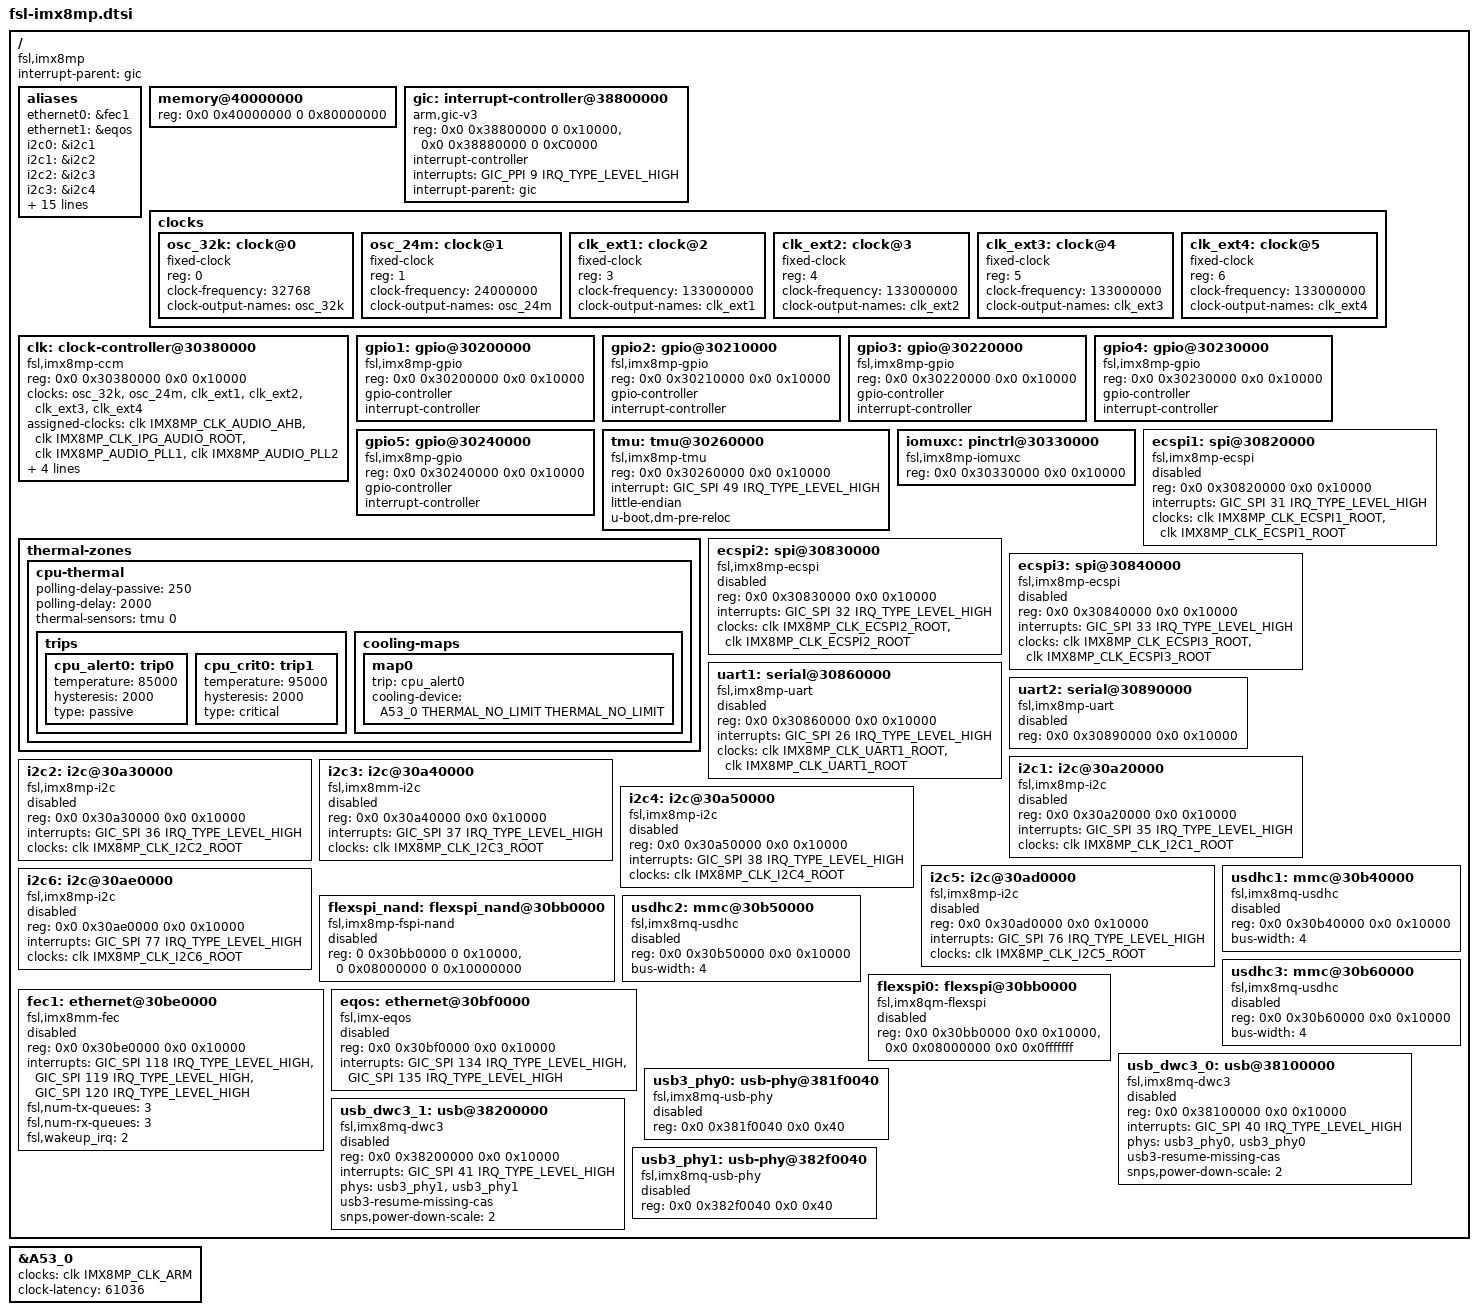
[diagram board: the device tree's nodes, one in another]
/*
 * Copyright 2019 NXP
 *
 * This program is free software; you can redistribute it and/or
 * modify it under the terms of the GNU General Public License
 * as published by the Free Software Foundation; either version 2
 * of the License, or (at your option) any later version.
 *
 * This program is distributed in the hope that it will be useful,
 * but WITHOUT ANY WARRANTY; without even the implied warranty of
 * MERCHANTABILITY or FITNESS FOR A PARTICULAR PURPOSE.  See the
 * GNU General Public License for more details.
 */

#include "fsl-imx8-ca53.dtsi"
#include <dt-bindings/clock/imx8mp-clock.h>
#include <dt-bindings/gpio/gpio.h>
#include <dt-bindings/input/input.h>
#include <dt-bindings/interrupt-controller/arm-gic.h>
#include <dt-bindings/pinctrl/pins-imx8mp.h>
#include <dt-bindings/thermal/thermal.h>

/ {
	compatible = "fsl,imx8mp";
	interrupt-parent = <&gic>;
	#address-cells = <2>;
	#size-cells = <2>;

	aliases {
		ethernet0 = &fec1;
		ethernet1 = &eqos;
		i2c0 = &i2c1;
		i2c1 = &i2c2;
		i2c2 = &i2c3;
		i2c3 = &i2c4;
		i2c4 = &i2c5;
		i2c5 = &i2c6;
		serial0 = &uart1;
		serial1 = &uart2;
		gpio0 = &gpio1;
		gpio1 = &gpio2;
		gpio2 = &gpio3;
		gpio3 = &gpio4;
		gpio4 = &gpio5;
		mmc0 = &usdhc1;
		mmc1 = &usdhc2;
		mmc2 = &usdhc3;
		usb0 = &usb_dwc3_0;
		usb1 = &usb_dwc3_1;
		spi0 = &flexspi0;
	};

	memory@40000000 {
		device_type = "memory";
		reg = <0x0 0x40000000 0 0x80000000>;
	};

	gic: interrupt-controller@38800000 {
		compatible = "arm,gic-v3";
		reg = <0x0 0x38800000 0 0x10000>, /* GIC Dist */
		      <0x0 0x38880000 0 0xC0000>; /* GICR (RD_base + SGI_base) */
		#interrupt-cells = <3>;
		interrupt-controller;
		interrupts = <GIC_PPI 9 IRQ_TYPE_LEVEL_HIGH>;
		interrupt-parent = <&gic>;
	};

	clocks {
		#address-cells = <1>;
		#size-cells = <0>;

		osc_32k: clock@0 {
			compatible = "fixed-clock";
			reg = <0>;
			#clock-cells = <0>;
			clock-frequency = <32768>;
			clock-output-names = "osc_32k";
		};

		osc_24m: clock@1 {
			compatible = "fixed-clock";
			reg = <1>;
			#clock-cells = <0>;
			clock-frequency = <24000000>;
			clock-output-names = "osc_24m";
		};

		clk_ext1: clock@2 {
			compatible = "fixed-clock";
			reg = <3>;
			#clock-cells = <0>;
			clock-frequency = <133000000>;
			clock-output-names = "clk_ext1";
		};

		clk_ext2: clock@3 {
			compatible = "fixed-clock";
			reg = <4>;
			#clock-cells = <0>;
			clock-frequency = <133000000>;
			clock-output-names = "clk_ext2";
		};

		clk_ext3: clock@4 {
			compatible = "fixed-clock";
			reg = <5>;
			#clock-cells = <0>;
			clock-frequency = <133000000>;
			clock-output-names = "clk_ext3";
		};

		clk_ext4: clock@5 {
			compatible = "fixed-clock";
			reg = <6>;
			#clock-cells = <0>;
			clock-frequency= <133000000>;
			clock-output-names = "clk_ext4";
		};
	};

	clk: clock-controller@30380000 {
		compatible = "fsl,imx8mp-ccm";
		reg = <0x0 0x30380000 0x0 0x10000>;
		#clock-cells = <1>;
		clocks = <&osc_32k>, <&osc_24m>, <&clk_ext1>, <&clk_ext2>,
			 <&clk_ext3>, <&clk_ext4>;
		clock-names = "osc_32k", "osc_24m", "clk_ext1", "clk_ext2",
			      "clk_ext3", "clk_ext4";
		assigned-clocks = <&clk IMX8MP_CLK_AUDIO_AHB>,
				  <&clk IMX8MP_CLK_IPG_AUDIO_ROOT>,
				  <&clk IMX8MP_AUDIO_PLL1>,
				  <&clk IMX8MP_AUDIO_PLL2>;
		assigned-clock-parents = <&clk IMX8MP_SYS_PLL1_800M>;
		assigned-clock-rates = <400000000>, <400000000>, <786432000>,
				       <722534400>;
	};

	gpio1: gpio@30200000 {
		compatible = "fsl,imx8mp-gpio", "fsl,imx35-gpio";
		reg = <0x0 0x30200000 0x0 0x10000>;
		gpio-controller;
		#gpio-cells = <2>;
		interrupt-controller;
		#interrupt-cells = <2>;
	};

	gpio2: gpio@30210000 {
		compatible = "fsl,imx8mp-gpio", "fsl,imx35-gpio";
		reg = <0x0 0x30210000 0x0 0x10000>;
		gpio-controller;
		#gpio-cells = <2>;
		interrupt-controller;
		#interrupt-cells = <2>;
	};

	gpio3: gpio@30220000 {
		compatible = "fsl,imx8mp-gpio", "fsl,imx35-gpio";
		reg = <0x0 0x30220000 0x0 0x10000>;
		gpio-controller;
		#gpio-cells = <2>;
		interrupt-controller;
		#interrupt-cells = <2>;
	};

	gpio4: gpio@30230000 {
		compatible = "fsl,imx8mp-gpio", "fsl,imx35-gpio";
		reg = <0x0 0x30230000 0x0 0x10000>;
		gpio-controller;
		#gpio-cells = <2>;
		interrupt-controller;
		#interrupt-cells = <2>;
	};

	gpio5: gpio@30240000 {
		compatible = "fsl,imx8mp-gpio", "fsl,imx35-gpio";
		reg = <0x0 0x30240000 0x0 0x10000>;
		gpio-controller;
		#gpio-cells = <2>;
		interrupt-controller;
		#interrupt-cells = <2>;
	};

	tmu: tmu@30260000 {
		compatible = "fsl,imx8mp-tmu";
		reg = <0x0 0x30260000 0x0 0x10000>;
		interrupt = <GIC_SPI 49 IRQ_TYPE_LEVEL_HIGH>;
		little-endian;
		u-boot,dm-pre-reloc;
		#thermal-sensor-cells =  <1>;
	};

	thermal-zones {
		/* cpu thermal */
		cpu-thermal {
			polling-delay-passive = <250>;
			polling-delay = <2000>;
			thermal-sensors = <&tmu 0>;
			trips {
				cpu_alert0: trip0 {
					temperature = <85000>;
					hysteresis = <2000>;
					type = "passive";
				};
				cpu_crit0: trip1 {
					temperature = <95000>;
					hysteresis = <2000>;
					type = "critical";
				};
			};

			cooling-maps {
				map0 {
					trip = <&cpu_alert0>;
					cooling-device =
					<&A53_0 THERMAL_NO_LIMIT THERMAL_NO_LIMIT>;
				};
			};
		};
	};

	iomuxc: pinctrl@30330000 {
		compatible = "fsl,imx8mp-iomuxc";
		reg = <0x0 0x30330000 0x0 0x10000>;
	};

	ecspi1: spi@30820000 {
		#address-cells = <1>;
		#size-cells = <0>;
		compatible = "fsl,imx8mp-ecspi", "fsl,imx51-ecspi";
		reg = <0x0 0x30820000 0x0 0x10000>;
		interrupts = <GIC_SPI 31 IRQ_TYPE_LEVEL_HIGH>;
		clocks = <&clk IMX8MP_CLK_ECSPI1_ROOT>,
			 <&clk IMX8MP_CLK_ECSPI1_ROOT>;
		clock-names = "ipg", "per";
		status = "disabled";
	};

	ecspi2: spi@30830000 {
		#address-cells = <1>;
		#size-cells = <0>;
		compatible = "fsl,imx8mp-ecspi", "fsl,imx51-ecspi";
		reg = <0x0 0x30830000 0x0 0x10000>;
		interrupts = <GIC_SPI 32 IRQ_TYPE_LEVEL_HIGH>;
		clocks = <&clk IMX8MP_CLK_ECSPI2_ROOT>,
			 <&clk IMX8MP_CLK_ECSPI2_ROOT>;
		clock-names = "ipg", "per";
		status = "disabled";
	};

	ecspi3: spi@30840000 {
		#address-cells = <1>;
		#size-cells = <0>;
		compatible = "fsl,imx8mp-ecspi", "fsl,imx51-ecspi";
		reg = <0x0 0x30840000 0x0 0x10000>;
		interrupts = <GIC_SPI 33 IRQ_TYPE_LEVEL_HIGH>;
		clocks = <&clk IMX8MP_CLK_ECSPI3_ROOT>,
			 <&clk IMX8MP_CLK_ECSPI3_ROOT>;
		clock-names = "ipg", "per";
		status = "disabled";
	};

	uart1: serial@30860000 {
		 compatible = "fsl,imx8mp-uart",
			      "fsl,imx6q-uart", "fsl,imx21-uart";
		 reg = <0x0 0x30860000 0x0 0x10000>;
		 interrupts = <GIC_SPI 26 IRQ_TYPE_LEVEL_HIGH>;
		 clocks = <&clk IMX8MP_CLK_UART1_ROOT>,
			 <&clk IMX8MP_CLK_UART1_ROOT>;
		 clock-names = "ipg", "per";
		 status = "disabled";
	};

	uart2: serial@30890000 {
		compatible = "fsl,imx8mp-uart",
			     "fsl,imx6q-uart", "fsl,imx21-uart";
		reg = <0x0 0x30890000 0x0 0x10000>;
		status = "disabled";
	};

	i2c1: i2c@30a20000 {
		#address-cells = <1>;
		#size-cells = <0>;
		compatible = "fsl,imx8mp-i2c", "fsl,imx21-i2c";
		reg = <0x0 0x30a20000 0x0 0x10000>;
		interrupts = <GIC_SPI 35 IRQ_TYPE_LEVEL_HIGH>;
		clocks = <&clk IMX8MP_CLK_I2C1_ROOT>;
		status = "disabled";
	};

	i2c2: i2c@30a30000 {
		#address-cells = <1>;
		#size-cells = <0>;
		compatible = "fsl,imx8mp-i2c", "fsl,imx21-i2c";
		reg = <0x0 0x30a30000 0x0 0x10000>;
		interrupts = <GIC_SPI 36 IRQ_TYPE_LEVEL_HIGH>;
		clocks = <&clk IMX8MP_CLK_I2C2_ROOT>;
		status = "disabled";
	};

	i2c3: i2c@30a40000 {
		#address-cells = <1>;
		#size-cells = <0>;
		compatible = "fsl,imx8mm-i2c", "fsl,imx21-i2c";
		reg = <0x0 0x30a40000 0x0 0x10000>;
		interrupts = <GIC_SPI 37 IRQ_TYPE_LEVEL_HIGH>;
		clocks = <&clk IMX8MP_CLK_I2C3_ROOT>;
		status = "disabled";
	};

	i2c4: i2c@30a50000 {
		#address-cells = <1>;
		#size-cells = <0>;
		compatible = "fsl,imx8mp-i2c", "fsl,imx21-i2c";
		reg = <0x0 0x30a50000 0x0 0x10000>;
		interrupts = <GIC_SPI 38 IRQ_TYPE_LEVEL_HIGH>;
		clocks = <&clk IMX8MP_CLK_I2C4_ROOT>;
		status = "disabled";
	};

	i2c5: i2c@30ad0000 {
		#address-cells = <1>;
		#size-cells = <0>;
		compatible = "fsl,imx8mp-i2c", "fsl,imx21-i2c";
		reg = <0x0 0x30ad0000 0x0 0x10000>;
		interrupts = <GIC_SPI 76 IRQ_TYPE_LEVEL_HIGH>;
		clocks = <&clk IMX8MP_CLK_I2C5_ROOT>;
		status = "disabled";
	};

	i2c6: i2c@30ae0000 {
		#address-cells = <1>;
		#size-cells = <0>;
		compatible = "fsl,imx8mp-i2c", "fsl,imx21-i2c";
		reg = <0x0 0x30ae0000 0x0 0x10000>;
		interrupts = <GIC_SPI 77 IRQ_TYPE_LEVEL_HIGH>;
		clocks = <&clk IMX8MP_CLK_I2C6_ROOT>;
		status = "disabled";
	};

	flexspi_nand: flexspi_nand@30bb0000 {
		#address-cells = <1>;
		#size-cells = <0>;
		compatible = "fsl,imx8mp-fspi-nand";
		reg = <0 0x30bb0000 0 0x10000>, <0 0x08000000 0 0x10000000>;
		reg-names = "FlexSPI", "FlexSPI-memory";
		status = "disabled";
	};

	usdhc1: mmc@30b40000 {
		compatible = "fsl,imx8mq-usdhc", "fsl,imx7d-usdhc";
		reg = <0x0 0x30b40000 0x0 0x10000>;
		bus-width = <4>;
		status = "disabled";
	};

	usdhc2: mmc@30b50000 {
		compatible = "fsl,imx8mq-usdhc", "fsl,imx7d-usdhc";
		reg = <0x0 0x30b50000 0x0 0x10000>;
		bus-width = <4>;
		status = "disabled";
	};

	usdhc3: mmc@30b60000 {
		compatible = "fsl,imx8mq-usdhc", "fsl,imx7d-usdhc";
		reg = <0x0 0x30b60000 0x0 0x10000>;
		bus-width = <4>;
		status = "disabled";
	};

	flexspi0: flexspi@30bb0000 {
		#address-cells = <1>;
		#size-cells = <0>;
		compatible = "fsl,imx8qm-flexspi";
		reg = <0x0 0x30bb0000 0x0 0x10000>,
		      <0x0 0x08000000 0x0 0x0fffffff>;
		reg-names = "FlexSPI", "FlexSPI-memory";
		clock-names = "qspi_en", "qspi";
		status = "disabled";
	};

	fec1: ethernet@30be0000 {
		compatible = "fsl,imx8mm-fec", "fsl,imx8mq-fec", "fsl,imx6sx-fec";
		reg = <0x0 0x30be0000 0x0 0x10000>;
		interrupts = <GIC_SPI 118 IRQ_TYPE_LEVEL_HIGH>,
			     <GIC_SPI 119 IRQ_TYPE_LEVEL_HIGH>,
			     <GIC_SPI 120 IRQ_TYPE_LEVEL_HIGH>;
#if 0
		clocks = <&clk IMX8MM_CLK_ENET1_ROOT>,
			 <&clk IMX8MM_CLK_ENET1_ROOT>,
			 <&clk IMX8MM_CLK_ENET_TIMER_DIV>,
			 <&clk IMX8MM_CLK_ENET_REF_DIV>,
			 <&clk IMX8MM_CLK_ENET_PHY_REF_DIV>;
		clock-names = "ipg", "ahb", "ptp",
			"enet_clk_ref", "enet_out";
		assigned-clocks = <&clk IMX8MM_CLK_ENET_AXI_SRC>,
				  <&clk IMX8MM_CLK_ENET_TIMER_SRC>,
				  <&clk IMX8MM_CLK_ENET_REF_SRC>,
				  <&clk IMX8MM_CLK_ENET_TIMER_DIV>;
		assigned-clock-parents = <&clk IMX8MM_SYS_PLL1_266M>,
					 <&clk IMX8MM_SYS_PLL2_100M>,
					 <&clk IMX8MM_SYS_PLL2_125M>;
		assigned-clock-rates = <0>, <0>, <125000000>, <100000000>;
#endif
		fsl,num-tx-queues=<3>;
		fsl,num-rx-queues=<3>;
		fsl,wakeup_irq = <2>;
		status = "disabled";
	};

	eqos: ethernet@30bf0000 {
		compatible = "fsl,imx-eqos";
		reg = <0x0 0x30bf0000 0x0 0x10000>;
		interrupts = <GIC_SPI 134 IRQ_TYPE_LEVEL_HIGH>,
			     <GIC_SPI 135 IRQ_TYPE_LEVEL_HIGH>;
		interrupt-names = "pmt", "macirq";
		status = "disabled";
	};

	usb_dwc3_0: usb@38100000 {
		compatible = "fsl,imx8mq-dwc3", "snps,dwc3";
		reg = <0x0 0x38100000 0x0 0x10000>;
		interrupts = <GIC_SPI 40 IRQ_TYPE_LEVEL_HIGH>;
		phys = <&usb3_phy0>, <&usb3_phy0>;
		phy-names = "usb2-phy", "usb3-phy";
		usb3-resume-missing-cas;
		snps,power-down-scale = <2>;
		status = "disabled";
	};

	usb3_phy0: usb-phy@381f0040 {
		compatible = "fsl,imx8mq-usb-phy";
		reg = <0x0 0x381f0040 0x0 0x40>;
		#phy-cells = <0>;
		status = "disabled";
	};

	usb_dwc3_1: usb@38200000 {
		compatible = "fsl,imx8mq-dwc3", "snps,dwc3";
		reg = <0x0 0x38200000 0x0 0x10000>;
		interrupts = <GIC_SPI 41 IRQ_TYPE_LEVEL_HIGH>;
		phys = <&usb3_phy1>, <&usb3_phy1>;
		phy-names = "usb2-phy", "usb3-phy";
		usb3-resume-missing-cas;
		snps,power-down-scale = <2>;
		status = "disabled";
	};

	usb3_phy1: usb-phy@382f0040 {
		compatible = "fsl,imx8mq-usb-phy";
		reg = <0x0 0x382f0040 0x0 0x40>;
		#phy-cells = <0>;
		status = "disabled";
	};
};

&A53_0 {
	clocks = <&clk IMX8MP_CLK_ARM>;
	clock-latency = <61036>;
	#cooling-cells = <2>;
};
